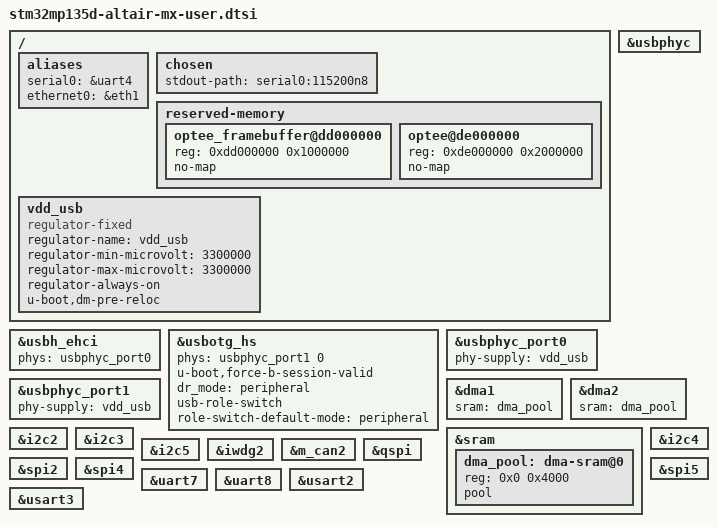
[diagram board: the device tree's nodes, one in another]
/ {
	aliases {
		serial0 = &uart4;
		ethernet0 = &eth1;
	};

	chosen {
		#address-cells = <1>;
		#size-cells = <1>;
		ranges;
		stdout-path = "serial0:115200n8";
	};

	reserved-memory {
		#address-cells = <1>;
		#size-cells = <1>;
		ranges;

		optee_framebuffer@dd000000 {
			reg = <0xdd000000 0x1000000>;
			no-map;
		};

		optee@de000000 {
			reg = <0xde000000 0x2000000>;
			no-map;
		};
	};

	vdd_usb: vdd_usb {
		compatible = "regulator-fixed";
		regulator-name = "vdd_usb";
		regulator-min-microvolt = <3300000>;
		regulator-max-microvolt = <3300000>;
		regulator-always-on;
	};
};

&usbh_ehci {
	phys = <&usbphyc_port0>;
	status = "okay";
};

&usbotg_hs {
	phys = <&usbphyc_port1 0>;
	u-boot,force-b-session-valid;
	// u-boot,force-vbus-detection;
	dr_mode = "peripheral";
	usb-role-switch;
	role-switch-default-mode = "peripheral";
	status = "okay";
};

&usbphyc {
	status = "okay";
};

&usbphyc_port0 {
	phy-supply = <&vdd_usb>;
};

&usbphyc_port1 {
	phy-supply = <&vdd_usb>;
};

&vdd_usb {
	u-boot,dm-pre-reloc;
};

&dma1 {
	sram = <&dma_pool>;
};

&dma2 {
	sram = <&dma_pool>;
};

&sram {
	dma_pool: dma-sram@0 {
		reg = <0x0 0x4000>;
		pool;
	};
};

// &i2c1 {
// 	/delete-property/dmas;
// 	/delete-property/dma-names;
// };

&i2c2 {
	/delete-property/dmas;
	/delete-property/dma-names;
};

&i2c3 {
	/delete-property/dmas;
	/delete-property/dma-names;
};

&i2c4 {
	/delete-property/dmas;
	/delete-property/dma-names;
};

&i2c5 {
	/delete-property/dmas;
	/delete-property/dma-names;
};

&iwdg2 {
	/delete-property/dmas;
	/delete-property/dma-names;
};

&m_can2 {
	/delete-property/dmas;
	/delete-property/dma-names;
};

// Comment out if we are using QSPI version
&qspi {
	/delete-property/dmas;
	/delete-property/dma-names;
};

// &spi1 {
// 	/delete-property/dmas;
// 	/delete-property/dma-names;
// };

&spi2 {
	/delete-property/dmas;
	/delete-property/dma-names;
};

&spi4 {
	/delete-property/dmas;
	/delete-property/dma-names;
};

&spi5 {
	/delete-property/dmas;
	/delete-property/dma-names;
};

// &uart4 {
// 	/delete-property/dmas;
// 	/delete-property/dma-names;
// };

// &uart5 {
// 	/delete-property/dmas;
// 	/delete-property/dma-names;
// };

&uart7 {
	/delete-property/dmas;
	/delete-property/dma-names;
};

&uart8 {
	/delete-property/dmas;
	/delete-property/dma-names;
};

&usart2 {
	/delete-property/dmas;
	/delete-property/dma-names;
};

&usart3 {
	/delete-property/dmas;
	/delete-property/dma-names;
};
